AUTOSAR XML (schema 00046)
package /DoorLock_indication_SWC_package
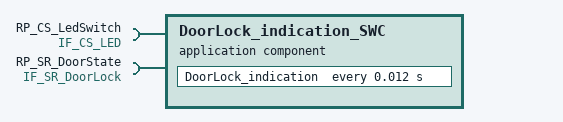
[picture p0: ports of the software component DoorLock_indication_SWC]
  application sw component type DoorLock_indication_SWC
    require port RP_CS_LedSwitch: client-com-spec=Led_Switch, required-interface=IF_CS_LED
    require port RP_SR_DoorState: nonqueued-receiver-com-spec{data-element=DoorState, init-value=DoorState:0}, required-interface=IF_SR_DoorLock
    behavior DoorLock_indication_SWC_internal_behavior
      timing event TE_12ms_event: start-on-event=DoorLock_indication, period=0.012
      runnable DoorLock_indication: symbol=DoorLock_indication_runnable
        data-read-access:
          access DoorLock_indication_RP_SR_DoorState_DoorState: accessed-variable=RP_SR_DoorState.DoorState
